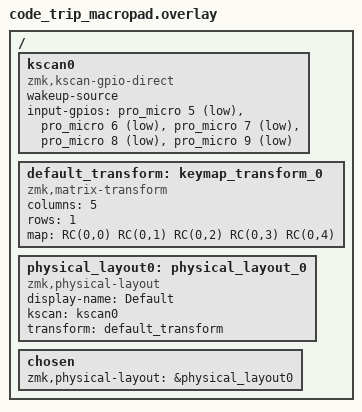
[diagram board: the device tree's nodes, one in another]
#include <dt-bindings/zmk/matrix_transform.h>

/ {
    kscan0: kscan0 {
        compatible = "zmk,kscan-gpio-direct";
        wakeup-source;
        input-gpios
            = <&pro_micro 5 (GPIO_ACTIVE_LOW | GPIO_PULL_UP)>
            , <&pro_micro 6 (GPIO_ACTIVE_LOW | GPIO_PULL_UP)>
            , <&pro_micro 7 (GPIO_ACTIVE_LOW | GPIO_PULL_UP)>
            , <&pro_micro 8 (GPIO_ACTIVE_LOW | GPIO_PULL_UP)>
            , <&pro_micro 9 (GPIO_ACTIVE_LOW | GPIO_PULL_UP)>
            ;
    };

    default_transform: keymap_transform_0 {
        compatible = "zmk,matrix-transform";
        columns = <5>;
        rows = <1>;
        map = <RC(0,0) RC(0,1) RC(0,2) RC(0,3) RC(0,4)>;
    };

    physical_layout0: physical_layout_0 {
        compatible = "zmk,physical-layout";
        display-name = "Default";
        kscan = <&kscan0>;
        transform = <&default_transform>;
    };

    chosen {
        zmk,physical-layout = &physical_layout0;
    };
};
